# ATSAM3U1C register map
Vendor: Atmel; File version: 0
CPU: CM3 r2p0, selectable endian, no MPU, no FPU, 0x4 interrupt priority bits, 0x0 interrupts
Registers are 32-bit, read-write, no defined reset value unless marked. A register's access mark holds for its fields unless they carry their own. Offsets are from the block's base; [hi:lo] are bit positions; {n}, {i} and the like mark numbered series; 'fields as' and 'values as' point back to an identical list.

## SUPC — Supply Controller
Base 0x400E1210; register names take the prefix SUPC_
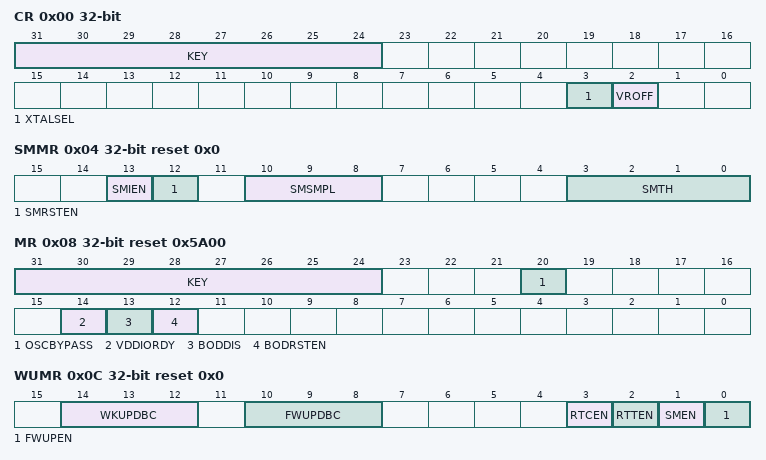
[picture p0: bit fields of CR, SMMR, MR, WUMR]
0x00 CR wo — Supply Controller Control Register
  [31:24] KEY — Password
    165=PASSWD (Writing any other value in this field aborts the write operation.)
  [3] XTALSEL — Crystal Oscillator Select
    0=NO_EFFECT; 1=CRYSTAL_SEL (if KEY is correct, switches the slow clock on the crystal oscillator output.)
  [2] VROFF — Voltage Regulator Off
    0=NO_EFFECT; 1=STOP_VREG (if KEY is correct, asserts the vddcore_nreset and stops the voltage regulator.)
0x04 SMMR reset 0x0 — Supply Controller Supply Monitor Mode Register
  [13] SMIEN — Supply Monitor Interrupt Enable
    0=NOT_ENABLE (the SUPC interrupt signal is not affected when a supply monitor detection occurs.); 1=ENABLE (the SUPC interrupt signal is asserted when a supply monitor detection occurs.)
  [12] SMRSTEN — Supply Monitor Reset Enable
    0=NOT_ENABLE (the core reset signal "vddcore_nreset" is not affected when a supply monitor detection occurs.); 1=ENABLE (the core reset signal, vddcore_nreset is asserted when a supply monitor detection occurs.)
  [10:8] SMSMPL — Supply Monitor Sampling Period
    0=SMD (Supply Monitor disabled); 1=CSM (Continuous Supply Monitor); 2=32SLCK (Supply Monitor enabled one SLCK period every 32 SLCK periods); 3=256SLCK (Supply Monitor enabled one SLCK period every 256 SLCK periods); 4=2048SLCK (Supply Monitor enabled one SLCK period every 2,048 SLCK periods)
  [3:0] SMTH — Supply Monitor Threshold
0x08 MR reset 0x5A00 — Supply Controller Mode Register
  [31:24] KEY — Password Key
    values as CR.KEY
  [20] OSCBYPASS — Oscillator Bypass
    0=NO_EFFECT (no effect. Clock selection depends on XTALSEL value.); 1=BYPASS (the 32-KHz XTAL oscillator is selected and is put in bypass mode.)
  [14] VDDIORDY — VDDIO Ready
    0=VDDIO_REMOVED (VDDIO is removed (used before going to backup mode when backup batteries are used)); 1=VDDIO_PRESENT (VDDIO is present (used before going to backup mode when backup batteries are used))
  [13] BODDIS — Brownout Detector Disable
    0=ENABLE (the core brownout detector is enabled.); 1=DISABLE (the core brownout detector is disabled.)
  [12] BODRSTEN — Brownout Detector Reset Enable
    0=NOT_ENABLE (the core reset signal "vddcore_nreset" is not affected when a brownout detection occurs.); 1=ENABLE (the core reset signal, vddcore_nreset is asserted when a brownout detection occurs.)
0x0C WUMR reset 0x0 — Supply Controller Wake-up Mode Register
  [14:12] WKUPDBC — Wake-up Inputs Debouncer Period
    0=IMMEDIATE (Immediate, no debouncing, detected active at least on one Slow Clock edge.); 1=3_SCLK (WKUPx shall be in its active state for at least 3 SLCK periods); 2=32_SCLK (WKUPx shall be in its active state for at least 32 SLCK periods); 3=512_SCLK (WKUPx shall be in its active state for at least 512 SLCK periods); 4=4096_SCLK (WKUPx shall be in its active state for at least 4,096 SLCK periods); 5=32768_SCLK (WKUPx shall be in its active state for at least 32,768 SLCK periods)
  [10:8] FWUPDBC — Force Wake-up Debouncer Period
    0=IMMEDIATE (Immediate, no debouncing, detected active at least on one Slow Clock edge.); 1=3_SCLK (FWUP shall be low for at least 3 SLCK periods); 2=32_SCLK (FWUP shall be low for at least 32 SLCK periods); 3=512_SCLK (FWUP shall be low for at least 512 SLCK periods); 4=4096_SCLK (FWUP shall be low for at least 4,096 SLCK periods); 5=32768_SCLK (FWUP shall be low for at least 32,768 SLCK periods)
  [3] RTCEN — Real Time Clock Wake-up Enable
    0=NOT_ENABLE (the RTC alarm signal has no wake-up effect.); 1=ENABLE (the RTC alarm signal forces the wake-up of the core power supply.)
  [2] RTTEN — Real Time Timer Wake-up Enable
    0=NOT_ENABLE (the RTT alarm signal has no wake-up effect.); 1=ENABLE (the RTT alarm signal forces the wake-up of the core power supply.)
  [1] SMEN — Supply Monitor Wake-up Enable
    0=NOT_ENABLE (the supply monitor detection has no wake-up effect.); 1=ENABLE (the supply monitor detection forces the wake-up of the core power supply.)
  [0] FWUPEN — Force Wake-up Enable
    0=NOT_ENABLE (the Force Wake-up pin has no wake-up effect.); 1=ENABLE (the Force Wake-up pin low forces the wake-up of the core power supply.)
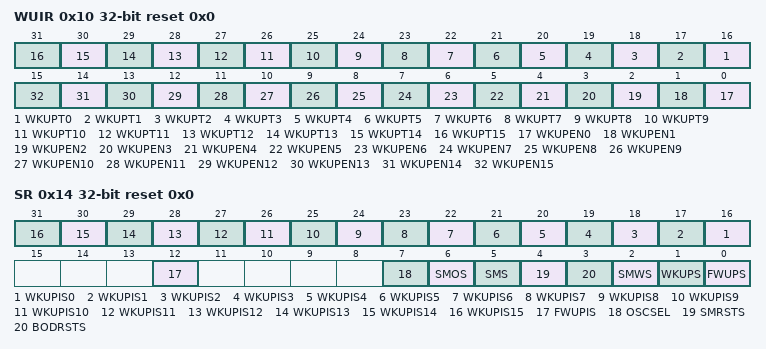
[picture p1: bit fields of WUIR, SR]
0x10 WUIR reset 0x0 — Supply Controller Wake-up Inputs Register
  [n+16] WKUPT{n} (n=0..15) — Wake-up Input Type {n}
    0=HIGH_TO_LOW (a high to low level transition for a period defined by WKUPDBC on the corresponding wake-up input forces the wake-up of the core power supply.); 1=LOW_TO_HIGH (a low to high level transition for a period defined by WKUPDBC on the correspond-ing wake-up input forces the wake-up of the core power supply.)
  [n] WKUPEN{n} (n=0..15) — Wake-up Input Enable {n}
    0=DISABLE (the corresponding wake-up input has no wake-up effect.); 1=ENABLE (the corresponding wake-up input forces the wake-up of the core power supply.)
0x14 SR ro reset 0x0 — Supply Controller Status Register
  [n+16] WKUPIS{n} (n=0..15) — WKUP Input Status {n}
    0=DIS (the corresponding wake-up input is disabled, or was inactive at the time the debouncer triggered a wake-up event.); 1=EN (the corresponding wake-up input was active at the time the debouncer triggered a wake-up event.)
  [12] FWUPIS — FWUP Input Status
    0=LOW (FWUP input is tied low.); 1=HIGH (FWUP input is tied high.)
  [7] OSCSEL — 32-kHz Oscillator Selection Status
    0=RC (the slow clock, SLCK is generated by the embedded 32-kHz RC oscillator.); 1=CRYST (the slow clock, SLCK is generated by the 32-kHz crystal oscillator.)
  [6] SMOS — Supply Monitor Output Status
    0=HIGH (the supply monitor detected VDDUTMI higher than its threshold at its last measurement.); 1=LOW (the supply monitor detected VDDUTMI lower than its threshold at its last measurement.)
  [5] SMS — Supply Monitor Status
    0=NO (no supply monitor detection since the last read of SUPC_SR.); 1=PRESENT (at least one supply monitor detection since the last read of SUPC_SR.)
  [4] SMRSTS — Supply Monitor Reset Status
    0=NO (no supply monitor detection has generated a core reset since the last read of the SUPC_SR.); 1=PRESENT (at least one supply monitor detection has generated a core reset since the last read of the SUPC_SR.)
  [3] BODRSTS — Brownout Detector Reset Status
    0=NO (no core brownout rising edge event has been detected since the last read of the SUPC_SR.); 1=PRESENT (at least one brownout output rising edge event has been detected since the last read of the SUPC_SR.)
  [2] SMWS — Supply Monitor Detection Wake-up Status
    0=NO (no wake-up due to a supply monitor detection has occurred since the last read of SUPC_SR.); 1=PRESENT (at least one wake-up due to a supply monitor detection has occurred since the last read of SUPC_SR.)
  [1] WKUPS — WKUP Wake-up Status
    0=NO (no wake-up due to the assertion of the WKUP pins has occurred since the last read of SUPC_SR.); 1=PRESENT (at least one wake-up due to the assertion of the WKUP pins has occurred since the last read of SUPC_SR.)
  [0] FWUPS — FWUP Wake-up Status
    0=NO (no wake-up due to the assertion of the FWUP pin has occurred since the last read of SUPC_SR.); 1=PRESENT (at least one wake-up due to the assertion of the FWUP pin has occurred since the last read of SUPC_SR.)
